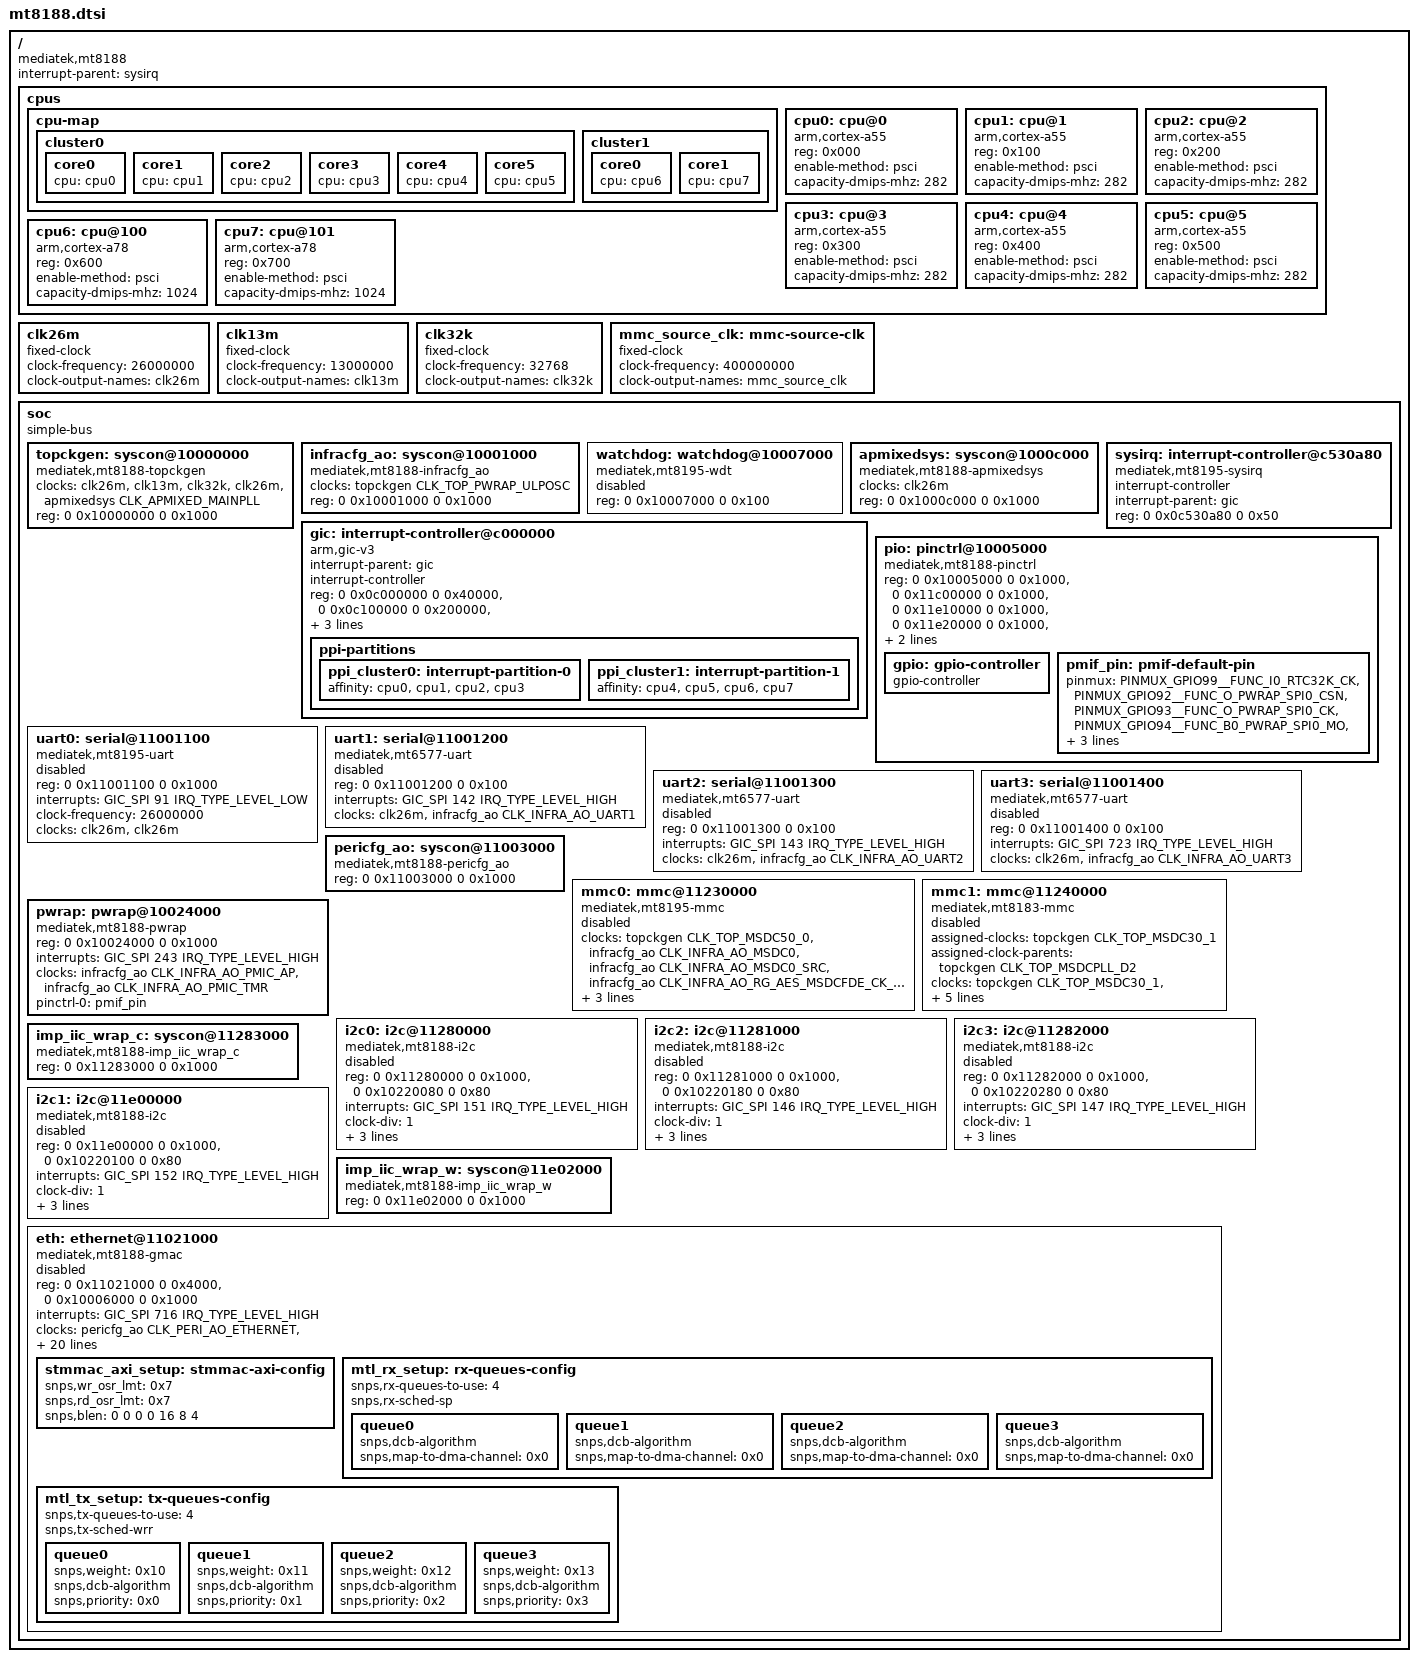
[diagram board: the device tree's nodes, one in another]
// SPDX-License-Identifier: (GPL-2.0 OR MIT)
/*
 * Copyright (C) 2022 MediaTek Inc.
 * Author: Chris-QJ Chen <chris-qj.chen@mediatek.com>
 *         Macpaul Lin <macpaul.lin@mediatek.com>
 */

#include <dt-bindings/clock/mediatek,mt8188-clk.h>
#include <dt-bindings/gpio/gpio.h>
#include <dt-bindings/interrupt-controller/irq.h>
#include <dt-bindings/interrupt-controller/arm-gic.h>
#include <dt-bindings/pinctrl/mediatek,mt8188-pinfunc.h>
#include <dt-bindings/phy/phy.h>

/ {
	compatible = "mediatek,mt8188";
	interrupt-parent = <&sysirq>;
	#address-cells = <2>;
	#size-cells = <2>;

	cpus {
		#address-cells = <1>;
		#size-cells = <0>;

		cpu-map {
			cluster0 {
				core0 {
					cpu = <&cpu0>;
				};
				core1 {
					cpu = <&cpu1>;
				};
				core2 {
					cpu = <&cpu2>;
				};
				core3 {
					cpu = <&cpu3>;
				};
				core4 {
					cpu = <&cpu4>;
				};
				core5 {
					cpu = <&cpu5>;
				};
			};
			cluster1 {
				core0 {
					cpu = <&cpu6>;
				};
				core1 {
					cpu = <&cpu7>;
				};
			};
		};

		cpu0: cpu@0 {
			device_type = "cpu";
			compatible = "arm,cortex-a55", "arm,armv8";
			reg = <0x000>;
			enable-method = "psci";
			capacity-dmips-mhz = <282>;
		};

		cpu1: cpu@1 {
			device_type = "cpu";
			compatible = "arm,cortex-a55", "arm,armv8";
			reg = <0x100>;
			enable-method = "psci";
			capacity-dmips-mhz = <282>;
		};

		cpu2: cpu@2 {
			device_type = "cpu";
			compatible = "arm,cortex-a55", "arm,armv8";
			reg = <0x200>;
			enable-method = "psci";
			capacity-dmips-mhz = <282>;
		};

		cpu3: cpu@3 {
			device_type = "cpu";
			compatible = "arm,cortex-a55", "arm,armv8";
			reg = <0x300>;
			enable-method = "psci";
			capacity-dmips-mhz = <282>;
		};

		cpu4: cpu@4 {
			device_type = "cpu";
			compatible = "arm,cortex-a55", "arm,armv8";
			reg = <0x400>;
			enable-method = "psci";
			capacity-dmips-mhz = <282>;
		};

		cpu5: cpu@5 {
			device_type = "cpu";
			compatible = "arm,cortex-a55", "arm,armv8";
			reg = <0x500>;
			enable-method = "psci";
			capacity-dmips-mhz = <282>;
		};

		cpu6: cpu@100 {
			device_type = "cpu";
			compatible = "arm,cortex-a78", "arm,armv8";
			reg = <0x600>;
			enable-method = "psci";
			capacity-dmips-mhz = <1024>;
		};

		cpu7: cpu@101 {
			device_type = "cpu";
			compatible = "arm,cortex-a78", "arm,armv8";
			reg = <0x700>;
			enable-method = "psci";
			capacity-dmips-mhz = <1024>;
		};
	};

	clk26m: clk26m {
		compatible = "fixed-clock";
		#clock-cells = <0>;
		clock-frequency = <26000000>;
		clock-output-names = "clk26m";
	};

	clk13m: clk13m {
		compatible = "fixed-clock";
		#clock-cells = <0>;
		clock-frequency = <13000000>;
		clock-output-names = "clk13m";
	};

	clk32k: clk32k {
		compatible = "fixed-clock";
		#clock-cells = <0>;
		clock-frequency = <32768>;
		clock-output-names = "clk32k";
	};

	mmc_source_clk: mmc-source-clk{
		compatible = "fixed-clock";
		#clock-cells = <0>;
		clock-frequency = <400000000>;
		clock-output-names = "mmc_source_clk";
	};

	soc {
		#address-cells = <2>;
		#size-cells = <2>;
		compatible = "simple-bus";
		ranges;

		topckgen: syscon@10000000 {
			clocks = <&clk26m>, <&clk13m>, <&clk32k>, <&clk26m>, <&apmixedsys CLK_APMIXED_MAINPLL>;
			clock-names = "clk26m", "clk13m", "clk32k", "ulposc_ck1", "mainpll_ck";
			compatible = "mediatek,mt8188-topckgen", "syscon";
			reg = <0 0x10000000 0 0x1000>;
			#clock-cells = <1>;
		};

		infracfg_ao: syscon@10001000 {
			clocks = <&topckgen CLK_TOP_PWRAP_ULPOSC>;
			clock-names = "wrap_ulposc";
			compatible = "mediatek,mt8188-infracfg_ao", "syscon", "simple-mfd";
			reg = <0 0x10001000 0 0x1000>;
			#clock-cells = <1>;
#if 0
			#reset-cells = <1>;
#endif
		};

		watchdog: watchdog@10007000 {
			compatible = "mediatek,mt8195-wdt",
				      "mediatek,wdt";
			reg = <0 0x10007000 0 0x100>;
			status = "disabled";
		};

		apmixedsys: syscon@1000c000 {
			clocks = <&clk26m>;
			clock-names = "clk26m";
			compatible = "mediatek,mt8188-apmixedsys", "syscon";
			reg = <0 0x1000c000 0 0x1000>;
			#clock-cells = <1>;
		};

		gic: interrupt-controller@c000000 {
			compatible = "arm,gic-v3";
			#interrupt-cells = <4>;
			interrupt-parent = <&gic>;
			interrupt-controller;
			reg = <0 0x0c000000 0 0x40000>,  /* GICD */
			      <0 0x0c100000 0 0x200000>, /* GICR */
			      <0 0x0c400000 0 0x2000>,   /* GICC */
			      <0 0x0c410000 0 0x1000>,   /* GICH */
			      <0 0x0c420000 0 0x2000>;   /* GICV */

			interrupts = <GIC_PPI 9 IRQ_TYPE_LEVEL_HIGH 0>;
			ppi-partitions {
				ppi_cluster0: interrupt-partition-0 {
					affinity = <&cpu0 &cpu1 &cpu2 &cpu3>;
				};
				ppi_cluster1: interrupt-partition-1 {
					affinity = <&cpu4 &cpu5 &cpu6 &cpu7>;
				};
			};
		};

		sysirq: interrupt-controller@c530a80 {
			compatible = "mediatek,mt8195-sysirq",
				     "mediatek,mt6577-sysirq";
			interrupt-controller;
			#interrupt-cells = <3>;
			interrupt-parent = <&gic>;
			reg = <0 0x0c530a80 0 0x50>;
		};

		pio: pinctrl@10005000 {
			compatible = "mediatek,mt8188-pinctrl";
			reg = <0 0x10005000 0 0x1000>,
			<0 0x11c00000 0 0x1000>,
			<0 0x11e10000 0 0x1000>,
			<0 0x11e20000 0 0x1000>,
			<0 0x11ea0000 0 0x1000>,
			<0 0x1000b000 0 0x1000>;
			reg-names = "iocfg0", "iocfg_rm", "iocfg_lt",
				    "iocfg_lm", "iocfg_rt", "eint";
			interrupt-controller;
			#interrupt-cells = <2>;

			gpio: gpio-controller {
				gpio-controller;
				#gpio-cells = <2>;
			};

			pmif_pin: pmif-default-pin {
				pinmux = <PINMUX_GPIO99__FUNC_I0_RTC32K_CK>,
					 <PINMUX_GPIO92__FUNC_O_PWRAP_SPI0_CSN>,
					 <PINMUX_GPIO93__FUNC_O_PWRAP_SPI0_CK>,
					 <PINMUX_GPIO94__FUNC_B0_PWRAP_SPI0_MO>,
					 <PINMUX_GPIO95__FUNC_B0_PWRAP_SPI0_MI>,
					 <PINMUX_GPIO175__FUNC_B0_SPMI_M_SCL>,
					 <PINMUX_GPIO176__FUNC_B0_SPMI_M_SDA>;
			};
		};

		uart0: serial@11001100 {
			compatible = "mediatek,mt8195-uart",
				     "mediatek,hsuart";
			reg = <0 0x11001100 0 0x1000>;
			interrupts = <GIC_SPI 91 IRQ_TYPE_LEVEL_LOW>;
			clock-frequency = <26000000>;
			clocks = <&clk26m>, <&clk26m>;
			clock-names = "baud", "bus";
			status = "disabled";
		};

		uart1: serial@11001200 {
			compatible = "mediatek,mt6577-uart";
			reg = <0 0x11001200 0 0x100>;
			interrupts = <GIC_SPI 142 IRQ_TYPE_LEVEL_HIGH>;
			clocks = <&clk26m>, <&infracfg_ao CLK_INFRA_AO_UART1>;
			clock-names = "baud", "bus";
			status = "disabled";
		};

		uart2: serial@11001300 {
			compatible = "mediatek,mt6577-uart";
			reg = <0 0x11001300 0 0x100>;
			interrupts = <GIC_SPI 143 IRQ_TYPE_LEVEL_HIGH>;
			clocks = <&clk26m>, <&infracfg_ao CLK_INFRA_AO_UART2>;
			clock-names = "baud", "bus";
			status = "disabled";
		};

		uart3: serial@11001400 {
			compatible = "mediatek,mt6577-uart";
			reg = <0 0x11001400 0 0x100>;
			interrupts = <GIC_SPI 723 IRQ_TYPE_LEVEL_HIGH>;
			clocks = <&clk26m>, <&infracfg_ao CLK_INFRA_AO_UART3>;
			clock-names = "baud", "bus";
			status = "disabled";
		};

		pericfg_ao: syscon@11003000 {
			compatible = "mediatek,mt8188-pericfg_ao", "syscon";
			reg = <0 0x11003000 0 0x1000>;
			#clock-cells = <1>;
		};

		mmc0: mmc@11230000 {
			clocks = <&topckgen CLK_TOP_MSDC50_0>,
				 <&infracfg_ao CLK_INFRA_AO_MSDC0>,
				 <&infracfg_ao CLK_INFRA_AO_MSDC0_SRC>,
				 <&infracfg_ao CLK_INFRA_AO_RG_AES_MSDCFDE_CK_0P>;
			clock-names = "source", "hclk", "source_cg", "crypto_clk";
			compatible = "mediatek,mt8195-mmc",
				     "mediatek,mt8183-mmc";
			interrupts = <GIC_SPI 77 IRQ_TYPE_LEVEL_LOW>;
			reg = <0 0x11230000 0 0x1000>,
			      <0 0x11f50000 0 0x1000>;
			status = "disabled";
		};

		mmc1: mmc@11240000 {
			assigned-clocks = <&topckgen CLK_TOP_MSDC30_1>;
			assigned-clock-parents = <&topckgen CLK_TOP_MSDCPLL_D2>;
			clocks = <&topckgen CLK_TOP_MSDC30_1>,
				<&infracfg_ao CLK_INFRA_AO_MSDC1>,
				<&infracfg_ao CLK_INFRA_AO_MSDC1_SRC>;
			clock-names = "source", "hclk", "source_cg";
			compatible = "mediatek,mt8183-mmc";
			interrupts = <GIC_SPI 135 IRQ_TYPE_LEVEL_HIGH>;
			reg = <0 0x11240000 0 0x1000>,
			      <0 0x11eb0000 0 0x1000>;
			status = "disabled";
		};

		pwrap: pwrap@10024000 {
			compatible = "mediatek,mt8188-pwrap", "syscon";
			reg = <0 0x10024000 0 0x1000>;
			reg-names = "pwrap";
			interrupts = <GIC_SPI 243 IRQ_TYPE_LEVEL_HIGH>;
			clocks = <&infracfg_ao CLK_INFRA_AO_PMIC_AP>,
				 <&infracfg_ao CLK_INFRA_AO_PMIC_TMR>;
			clock-names = "spi", "wrap";
			pinctrl-names = "default";
			pinctrl-0 = <&pmif_pin>;
		};

		i2c0: i2c@11280000 {
			compatible = "mediatek,mt8188-i2c";
			reg = <0 0x11280000 0 0x1000>,
			      <0 0x10220080 0 0x80>;
			interrupts = <GIC_SPI 151 IRQ_TYPE_LEVEL_HIGH>;
			clock-div = <1>;
			clocks = <&imp_iic_wrap_c CLK_IMP_IIC_WRAP_C_AP_CLOCK_I2C0>,
				 <&infracfg_ao CLK_INFRA_AO_APDMA_BCLK>;
			clock-names = "main", "dma";
			#address-cells = <1>;
			#size-cells = <0>;
			status = "disabled";
		};

		i2c2: i2c@11281000 {
			compatible = "mediatek,mt8188-i2c";
			reg = <0 0x11281000 0 0x1000>,
				<0 0x10220180 0 0x80>;
			interrupts = <GIC_SPI 146 IRQ_TYPE_LEVEL_HIGH>;
			clock-div = <1>;
			clocks = <&imp_iic_wrap_c CLK_IMP_IIC_WRAP_C_AP_CLOCK_I2C2>,
				 <&infracfg_ao CLK_INFRA_AO_APDMA_BCLK>;
			clock-names = "main", "dma";
			#address-cells = <1>;
			#size-cells = <0>;
			status = "disabled";
		};

		i2c3: i2c@11282000 {
			compatible = "mediatek,mt8188-i2c";
			reg = <0 0x11282000 0 0x1000>,
			      <0 0x10220280 0 0x80>;
			interrupts = <GIC_SPI 147 IRQ_TYPE_LEVEL_HIGH>;
			clock-div = <1>;
			clocks = <&imp_iic_wrap_c CLK_IMP_IIC_WRAP_C_AP_CLOCK_I2C3>,
				 <&infracfg_ao CLK_INFRA_AO_APDMA_BCLK>;
			clock-names = "main", "dma";
			#address-cells = <1>;
			#size-cells = <0>;
			status = "disabled";
		};

		imp_iic_wrap_c: syscon@11283000 {
			compatible = "mediatek,mt8188-imp_iic_wrap_c", "syscon";
			reg = <0 0x11283000 0 0x1000>;
			#clock-cells = <1>;
		};

		i2c1: i2c@11e00000 {
			compatible = "mediatek,mt8188-i2c";
			reg = <0 0x11e00000 0 0x1000>,
			      <0 0x10220100 0 0x80>;
			interrupts = <GIC_SPI 152 IRQ_TYPE_LEVEL_HIGH>;
			clock-div = <1>;
			clocks = <&imp_iic_wrap_w CLK_IMP_IIC_WRAP_W_AP_CLOCK_I2C1>,
				 <&infracfg_ao CLK_INFRA_AO_APDMA_BCLK>;
			clock-names = "main", "dma";
			#address-cells = <1>;
			#size-cells = <0>;
			status = "disabled";
		};

		imp_iic_wrap_w: syscon@11e02000 {
			compatible = "mediatek,mt8188-imp_iic_wrap_w", "syscon";
			reg = <0 0x11e02000 0 0x1000>;
			#clock-cells = <1>;
		};

		eth: ethernet@11021000 {
			compatible = "mediatek,mt8188-gmac", "mediatek,mt8195-gmac",
				     "snps,dwmac-5.10a";
			/* TODO: remove it when power driver is ready*/
			reg = <0 0x11021000 0 0x4000>, <0 0x10006000 0 0x1000>;
			interrupts = <GIC_SPI 716 IRQ_TYPE_LEVEL_HIGH>;
			interrupt-names = "macirq";
			clock-names = "axi",
				      "apb",
				      "mac_cg",
				      "mac_main",
				      "ptp_ref",
				      "rmii_internal";
			clocks = <&pericfg_ao CLK_PERI_AO_ETHERNET>,
				 <&pericfg_ao CLK_PERI_AO_ETHERNET_BUS>,
				 <&pericfg_ao CLK_PERI_AO_ETHERNET_MAC>,
				 <&topckgen CLK_TOP_SNPS_ETH_250M>,
				 <&topckgen CLK_TOP_SNPS_ETH_62P4M_PTP>,
				 <&topckgen CLK_TOP_SNPS_ETH_50M_RMII>;
			assigned-clocks = <&topckgen CLK_TOP_SNPS_ETH_250M>,
					  <&topckgen CLK_TOP_SNPS_ETH_62P4M_PTP>,
					  <&topckgen CLK_TOP_SNPS_ETH_50M_RMII>;
			assigned-clock-parents = <&topckgen CLK_TOP_ETHPLL_D2>,
						 <&topckgen CLK_TOP_ETHPLL_D8>,
						 <&topckgen CLK_TOP_ETHPLL_D10>;
			mediatek,pericfg = <&infracfg_ao>;
			snps,axi-config = <&stmmac_axi_setup>;
			snps,mtl-rx-config = <&mtl_rx_setup>;
			snps,mtl-tx-config = <&mtl_tx_setup>;
			snps,txpbl = <16>;
			snps,rxpbl = <16>;
			snps,clk-csr = <0>;
			status = "disabled";

			stmmac_axi_setup: stmmac-axi-config {
				snps,wr_osr_lmt = <0x7>;
				snps,rd_osr_lmt = <0x7>;
				snps,blen = <0 0 0 0 16 8 4>;
			};

			mtl_rx_setup: rx-queues-config {
				snps,rx-queues-to-use = <4>;
				snps,rx-sched-sp;
				queue0 {
					snps,dcb-algorithm;
					snps,map-to-dma-channel = <0x0>;
				};
				queue1 {
					snps,dcb-algorithm;
					snps,map-to-dma-channel = <0x0>;
				};
				queue2 {
					snps,dcb-algorithm;
					snps,map-to-dma-channel = <0x0>;
				};
				queue3 {
					snps,dcb-algorithm;
					snps,map-to-dma-channel = <0x0>;
				};
			};
			mtl_tx_setup: tx-queues-config {
				snps,tx-queues-to-use = <4>;
				snps,tx-sched-wrr;
				queue0 {
					snps,weight = <0x10>;
					snps,dcb-algorithm;
					snps,priority = <0x0>;
				};
				queue1 {
					snps,weight = <0x11>;
					snps,dcb-algorithm;
					snps,priority = <0x1>;
				};
				queue2 {
					snps,weight = <0x12>;
					snps,dcb-algorithm;
					snps,priority = <0x2>;
				};
				queue3 {
					snps,weight = <0x13>;
					snps,dcb-algorithm;
					snps,priority = <0x3>;
				};
			};
		};
	};
};
